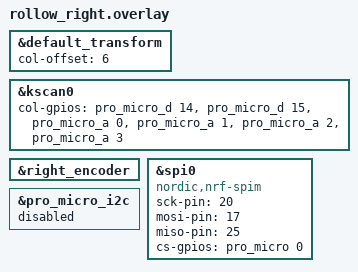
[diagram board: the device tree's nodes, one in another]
/*
 * Copyright (c) 2020 Pete Johanson
 *
 * SPDX-License-Identifier: MIT
 */

#include "rollow.dtsi"

&default_transform {
	col-offset = <6>;
};

&kscan0 {
	col-gpios
		= <&pro_micro_d 14 GPIO_ACTIVE_HIGH>
		, <&pro_micro_d 15 GPIO_ACTIVE_HIGH>
		, <&pro_micro_a  0 GPIO_ACTIVE_HIGH>
		, <&pro_micro_a  1 GPIO_ACTIVE_HIGH>
		, <&pro_micro_a  2 GPIO_ACTIVE_HIGH>
		, <&pro_micro_a  3 GPIO_ACTIVE_HIGH>
		;
};

&right_encoder {
	status = "okay";
};

nice_view_spi: &spi0 {
	compatible = "nordic,nrf-spim";
	sck-pin = <20>;
	mosi-pin = <17>;
	miso-pin = <25>;
	cs-gpios = <&pro_micro 0 GPIO_ACTIVE_HIGH>;
};

&pro_micro_i2c {
	status = "disabled";
};

